# NUC1xx_registers register map
File version: 0.1
CPU: 
Registers are 32-bit, read-write, reset 0x0 unless marked. A register's access mark holds for its fields unless they carry their own. Offsets are from the block's base; [hi:lo] are bit positions; lines under a group give offsets from that group.

## EBI — Registers group
Base 0x50010000
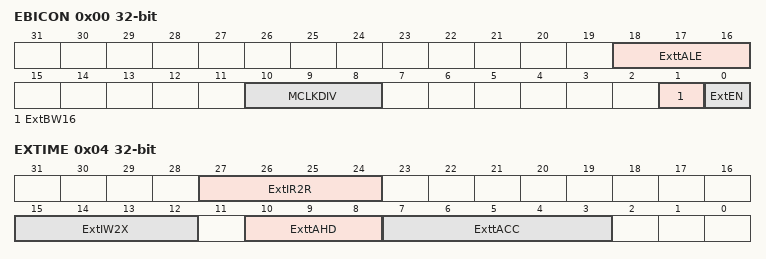
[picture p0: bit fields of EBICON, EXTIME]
0x00 EBICON — External Bus Interface General Control Register
  [18:16] ExttALE — Expand Time of ALE The ALE width (tALE) to latch the address can be controlled by ExttALE. tALE = (ExttALE+1)*MCLK
  [10:8] MCLKDIV — External Output Clock Divider The frequency of EBI output clock is controlled by MCLKDIV as follows table: MCLKDIV Output clock (MCLK) 000 HCLK/1 001 HCLK/2 010 HCLK/4 011 HCLK/8 100 HCLK/16 101 HCLK/32 11X default Notice: Default value of output clock is HCLK/1
  [1] ExtBW16 — EBI data width 16 bit This bit defines if the data bus is 8-bit or 16-bit. 1: EBI data width is 16 bit 0: EBI data width is 8 bit
  [0] ExtEN — EBI Enable This bit is the functional enable bit for EBI. 1: EBI function is enabled 0: EBI function is disabled
0x04 EXTIME — External Bus Interface Timing Control Register
  [27:24] ExtIR2R — Idle State Cycle Between Read-Read When read action is finish and next action is going to read, idle state is inserted and nCS return to high if ExtIR2R is not zero. Idle state cycle = (ExtIR2R)*MCLK
  [15:12] ExtIW2X — Idle State Cycle After Write When write action is finish, idle state is inserted and nCS return to high if ExtIW2X is not zero. Idle state cycle = (ExtIW2X)*MCLK
  [10:8] ExttAHD — EBI Data Access Hold Time ExttAHD define data access hold time (tAHD). tAHD = (ExttAHD+1)*MCLK
  [7:3] ExttACC — EBI Data Access Time ExttACC define data access time (tACC). tACC = (ExttACC+1)*MCLK

## FMC — Registers group
Base 0x5000C000
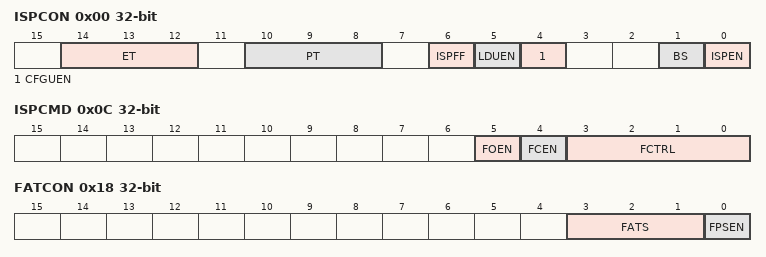
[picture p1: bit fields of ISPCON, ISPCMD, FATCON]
0x00 ISPCON — ISP Control Register
  [14:12] ET — Flash Erase Time ET[2] ET[1] ET[0] Erase Time (ms) 0 0 0 20 (default) 0 0 1 25 0 1 0 30 0 1 1 35 1 0 0 3 1 0 1 5 1 1 0 10 1 1 1 15
  [10:8] PT — Flash Program Time PT[2] PT[1] PT[0] Program Time (us) 0 0 0 40 0 0 1 45 0 1 0 50 0 1 1 55 1 0 0 20 1 0 1 25 1 1 0 30 1 1 1 35
  [6] ISPFF write-1-clears — ISP Fail Flag This bit is set by hardware when a triggered ISP meets any of the following conditions: (1) APROM writes to itself. (2) LDROM writes to itself. (3) CONFIG is erased/programmed if CFGUEN is set to 0. (4) Destination address is illegal, such as over an available range. Write 1 to clear.
  [5] LDUEN — LDROM Update Enable LDROM update enable bit. 1 = LDROM can be updated when the MCU runs in APROM. 0 = LDROM can not be updated
  [4] CFGUEN — Enable Config-bits Update by ISP LDROM update enable bit. 1 = Enable ISP can update config-bits. 0 = Disable ISP can update config-bits.
  [1] BS — Boot Select Set/clear this bit to select next booting from LDROM/APROM, respectively. This bit also functions as chip booting status flag, which can be used to check where chip booted from. This bit is initiated with the inversed value of CBS in Config0 after power-on reset; It keeps the same value at other reset. 1 = boot from LDROM 0 = boot from APROM
  [0] ISPEN — ISP Enable ISP function enable bit. Set this bit to enable ISP function. 1 = Enable ISP function 0 = Disable ISP function
0x04 ISPADR — ISP Address Register
  [31:0] ISPADR — ISP Address NuMicro(TM) NUC100 Series equips with a maximum 32Kx32 embedded flash, it supports word program only. ISPARD[1:0] must be kept 00b for ISP operation.
0x08 ISPDAT — ISP Data Register
  [31:0] ISPDAT — ISP Data Write data to this register before ISP program operation Read data from this register after ISP read operation
0x0C ISPCMD — ISP Command Register
  [5] FOEN — ISP Command ISP command table is showed below: Operation Mode FOEN FCEN FCTRL[3:0] Read 0 0 0 0 0 0 Program 1 0 0 0 0 1 Page Erase 1 0 0 0 1 0
  [4] FCEN — ISP Command ISP command table is showed below: Operation Mode FOEN FCEN FCTRL[3:0] Read 0 0 0 0 0 0 Program 1 0 0 0 0 1 Page Erase 1 0 0 0 1 0
  [3:0] FCTRL — ISP Command ISP command table is showed below: Operation Mode FOEN FCEN FCTRL[3:0] Read 0 0 0 0 0 0 Program 1 0 0 0 0 1 Page Erase 1 0 0 0 1 0
0x10 ISPTRG — ISP Trigger Control Register
  [0] ISPGO — ISP start trigger Write 1 to start ISP operation and this bit will be cleared to 0 by hardware automatically when ISP operation is finished. 1 = ISP is on going 0 = ISP is operation is finished
0x14 DFBADR ro reset 0x1F000 — Data Flash Base Address Register
  [31:0] DFBADR — Data Flash Base Address This register indicates data flash start address. It is a read only register. For 128kB flash memory device, the data flash size is defined by user configuration, register content is loaded from Config1 when chip power on but for 64/32kB device, it is fixed at 0x01_f000
0x18 FATCON — Flash Access Time Control Register
  [3:1] FATS — Flash Access Time Window Select These bits are used to decide flash sense amplifier active duration. FATS Access Time window (ns) 000 40 001 50 010 60 011 70 100 80 101 90 110 100 111 reserved
  [0] FPSEN — Flash Power Save Enable If CPU clock is slower than 24 MHz, then s/w can enable flash power saving function. 1 = Enable flash power saving 0 = Disable flash power saving
